# AC33GA256 register map
Vendor: ABOV Semiconductor Co., Ltd.; File version: 0.1
CPU: CM3 r1p0, little endian, no MPU, no FPU, 3 interrupt priority bits
Registers are 32-bit, read-write, reset 0x0 unless marked. A register's access mark holds for its fields unless they carry their own. Offsets are from the block's base; [hi:lo] are bit positions; {n}, {i} and the like mark numbered series.

## PMU — POWER MANAGEMENT UNIT
Base 0x40000000
0x00 IDR ro reset 0xCEDA0000 — Chip ID Register
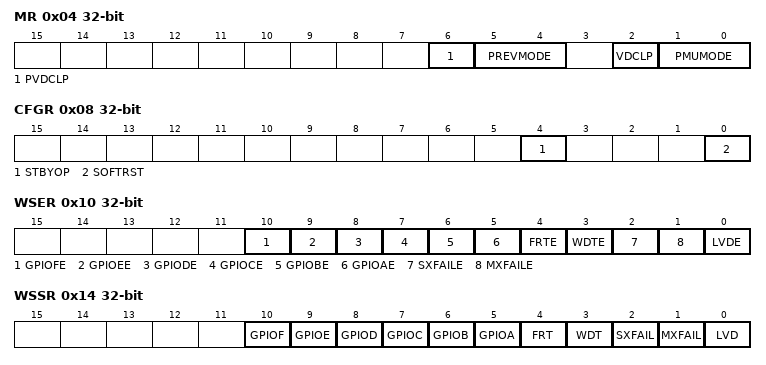
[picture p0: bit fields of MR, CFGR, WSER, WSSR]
0x04 MR — PMU Mode Register
  [6] PVDCLP, [5:4] PREVMODE, [2] VDCLP, [1:0] PMUMODE
0x08 CFGR — PMU CONFIGURATION REGISTER
  [4] STBYOP — Output polarity of STBY pin
  [0] SOFTRST — Setting for internal soft-reset
0x10 WSER — PMU Wake-up Source Enable Register
  [10] GPIOFE — Setting of the wake-up by GPIOF (PD SLEEP)
  [9] GPIOEE — Setting of the wake-up by GPIOE (PD SLEEP)
  [8] GPIODE — Setting of the wake-up by GPIOD (PD SLEEP)
  [7] GPIOCE — Setting of the wake-up by GPIOC (PD SLEEP)
  [6] GPIOBE — Setting of the wake-up by GPIOB (PD SLEEP)
  [5] GPIOAE — Setting of the wake-up by GPIO (PD SLEEP)
  [4] FRTE — Setting of the wake-up by FRT (PD SLEEP)
  [3] WDTE — Setting of the wake-up by WDT (PD SLEEP)
  [2] SXFAILE — Setting of the wake-up by the Sub OSC Fail Event(SLEEP)Setting value of the wake-up by LVD (SLEEP)
  [1] MXFAILE — Setting of the wake-up by Main OSC-fail event(SLEEP)Setting value of the wake-up by Sub OSC Fail Event (SLEEP)
  [0] LVDE — Setting of the wake-up by LVD (SLEEP)Setting value of the wake-up by Main OSC Fail Event (SLEEP)
0x14 WSSR — PMU Wak-up Source Status Register
  [10] GPIOF, [9] GPIOE, [8] GPIOD, [7] GPIOC, [6] GPIOB, [5] GPIOA, [4] FRT, [3] WDT, [2] SXFAIL, [1] MXFAIL, [0] LVD
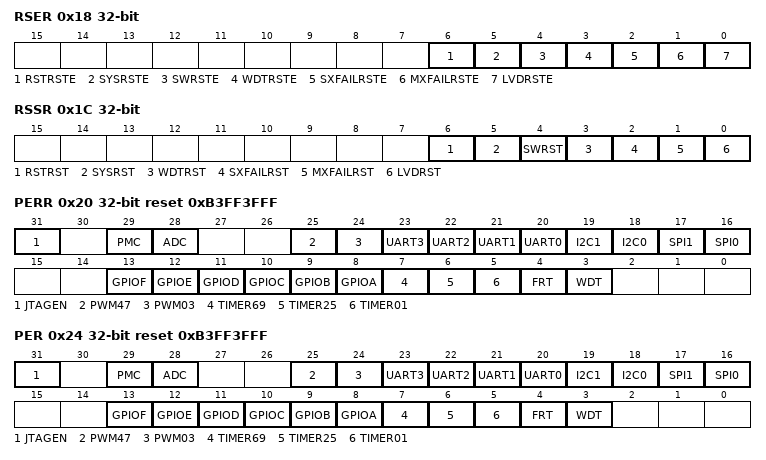
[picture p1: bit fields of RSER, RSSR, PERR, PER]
0x18 RSER — Reset Source Enable Register
  [6] RSTRSTE — Enable/Disable external nRESET pin reset
  [5] SYSRSTE — Enable/Disable SystemReset from the core
  [4] SWRSTE — Enable/Disable Software Reset in PMUCFGR
  [3] WDTRSTE — Enable/Disable WDT reset
  [2] SXFAILRSTE — Enable/Disable auxiliary oscillator failure reset
  [1] MXFAILRSTE — Enable/Disable auxiliary oscillator failure reset
  [0] LVDRSTE — Enable/Disable LVD reset
0x1C RSSR — Reset Source Status Register
  [6] RSTRST — Occurrence of external nRESET pin reset
  [5] SYSRST — Occurrence of SystemReset from the core
  [4] SWRST — Occurrence of Software Reset in PMUCFGR
  [3] WDTRST — Occurrence of WDT reset
  [2] SXFAILRST — Occurrence of auxiliary oscillator failure reset
  [1] MXFAILRST — Occurrence of auxiliary oscillator failure reset
  [0] LVDRST — Occurrence of LVD reset
0x20 PERR reset 0xB3FF3FFF — PMU Peripheral Event Reset Register
  [31] JTAGEN — Enable JTAG reset
  [29] PMC — Enable PMC (Port Map Controller) reset
  [28] ADC — Enable ADC reset
  [25] PWM47 — Enable PWM4, 5,6,7 reset
  [24] PWM03 — Enable PWM0, 1,2,3 reset
  [n+20] UART{n} (n=0..3) — Enable UART{n} reset
  [19] I2C1 — Enable I2C1 reset
  [18] I2C0 — Enable I2C0 reset
  [17] SPI1 — Enable SPI1 reset
  [16] SPI0 — Enable SPI0 reset
  [13] GPIOF — Enable GPIOF reset
  [12] GPIOE — Enable GPIOE reset
  [11] GPIOD — Enable GPIOD reset
  [10] GPIOC — Enable GPIOC reset
  [9] GPIOB — Enable GPIOB reset
  [8] GPIOA — Enable GPIOA reset
  [7] TIMER69 — Enable TIMER6, 7,8,9 reset
  [6] TIMER25 — Enable TIMER2, 3,4,5 reset
  [5] TIMER01 — Enable TIMER0, 1 reset
  [4] FRT — Enble Free-run Timer reset
  [3] WDT — Enabled Watchdog Timer reset
0x24 PER reset 0xB3FF3FFF — PMU Perpheral Enable Register
  [31] JTAGEN — JTAG enable - reset
  [29] PMC — Enable-Reset PMC
  [28] ADC — Enable-Reset ADC
  [25] PWM47 — Enable-Reset PWM4, 5,6,7
  [24] PWM03 — Enable-Reset PWM0, 1,2,3
  [n+20] UART{n} (n=0..3) — Enable-Reset UART{n}
  [19] I2C1 — Enable-Reset I2C1
  [18] I2C0 — Enable-Reset I2C0
  [17] SPI1 — Enable-Reset SPI1
  [16] SPI0 — Enable-Reset SPI0
  [13] GPIOF — Enable-Reset GPIOF
  [12] GPIOE — Enable-Reset GPIOE
  [11] GPIOD — Enable-Reset GPIOD
  [10] GPIOC — Enable-Reset GPIOC
  [9] GPIOB — Enable-Reset GPIOB
  [8] GPIOA — Enable-Reset GPIOA
  [7] TIMER69 — Enable-Reset TIMER6, 7,8,9
  [6] TIMER25 — Enable-Reset TIMER2, 3,4,5
  [5] TIMER01 — Enable-Reset TIMER0, 1
  [4] FRT — Enable-Reset Free-run Timer
  [3] WDT — Enable-Reset Watch-dog Timer
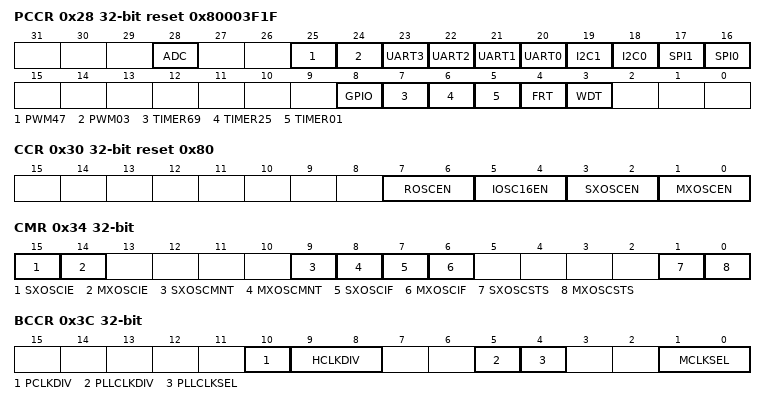
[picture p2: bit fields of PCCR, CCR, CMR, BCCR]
0x28 PCCR reset 0x80003F1F — PMU Peripheral Clock Control Register
  [28] ADC — Enable-Disable ADC clock
  [25] PWM47 — Enable-Disable PWM4, 5,6,7 clock
  [24] PWM03 — Enable-Disable PWM0, 1,2,3 clock
  [n+20] UART{n} (n=0..3) — Enable-Disable UART{n} clock
  [19] I2C1 — Enable-Disable I2C1 clock
  [18] I2C0 — Enable-Disable I2C0 clock
  [17] SPI1 — Enable-Disable SPI1 clock
  [16] SPI0 — Enable-Disable SPI0 clock
  [8] GPIO — Enable-Disable GPIO clock
  [7] TIMER69 — Enable-Disable TIMER6, 7,8,9 clock
  [6] TIMER25 — Enable-Disable TIMER2, 3,4,5 clock
  [5] TIMER01 — Enable-Disable TIMER0, 1 clock
  [4] FRT — Enable-Disable Free-run Timer clock
  [3] WDT — Enable-Disable Watch-dog Timer clock
0x30 CCR reset 0x80 — PMU Clock Control Register
  [7:6] ROSCEN — Enable internal ring oscillator
  [5:4] IOSC16EN — Enable internal 16MHz oscillator
  [3:2] SXOSCEN — Enable external sub-crystal oscillator
  [1:0] MXOSCEN — Enable external main crystal oscillator
0x34 CMR — PMU Clock Monitoring Register
  [15] SXOSCIE — Enable-Disable the interrupt event of monitoring external auxiliary crystal oscillation
  [14] MXOSCIE — Enable-Disable the interrupt event of monitoring external main crystal oscillation
  [9] SXOSCMNT — Enable-Disable the monitoring function of external auxiliary crystal oscillator
  [8] MXOSCMNT — Enable-Disable the monitoring function of external main crystal oscillator
  [7] SXOSCIF — Failure dectection flag of external auxiliary crystal oscillation (To clear this flag, write 1 to the bit)
  [6] MXOSCIF — Failure dectection flag of external main crystal oscillation (To clear this flag, write 1 to the bit)
  [1] SXOSCSTS — The oscillation status of external auxiliary crystal oscillation (To clear this flag, write 1 to the bit)
  [0] MXOSCSTS — The oscillation status of external main crystal oscillation (To clear this flag, write 1 to the bit)
0x3C BCCR — PMU BUS Clock Control Register
  [10] PCLKDIV — PCLK clock divider set
  [9:8] HCLKDIV — HCLK clock dvider set
  [5] PLLCLKDIV — PLL input clock divider
  [4] PLLCLKSEL — PLL input clock selection
  [1:0] MCLKSEL — Main clock source selection
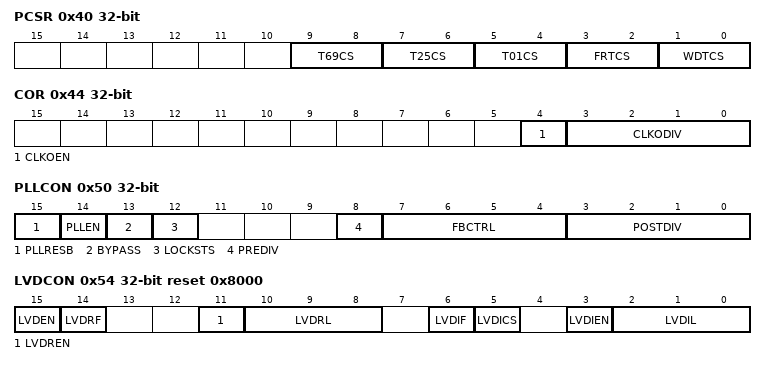
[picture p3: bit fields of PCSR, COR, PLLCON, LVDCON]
0x40 PCSR (reset mask 0x1FF) — PMU Peripheral Clock Select Register
  [9:8] T69CS — Select the timer 6,7,8,9 input clock
  [7:6] T25CS — Select timer 2,3,4,5 input clock
  [5:4] T01CS — Select timer 0,1 input clock
  [3:2] FRTCS — Select FRT input clock
  [1:0] WDTCS — Select WDT input clock
0x44 COR — PMU Clock Output Register
  [4] CLKOEN — Enable CLKO divider output
  [3:0] CLKODIV — set the value of the division of CLKO
0x50 PLLCON — PLL Control Register
  [15] PLLRESB — PLL Reset
  [14] PLLEN — PLL Enable
  [13] BYPASS — Select PLL input clock bypass
  [12] LOCKSTS ro — PLL Lock state
  [8] PREDIV — Pre-Divider division control
  [7:4] FBCTRL — Post-scaler control
  [3:0] POSTDIV — post divider
0x54 LVDCON reset 0x8000 — LVD Control Register
  [15] LVDEN — Enable LVD
  [14] LVDRF — LVD reset flag (cleared when writing 1)
  [11] LVDREN — Enable LVD Reset
  [10:8] LVDRL — Select LVD Reset voltage level
  [6] LVDIF — LVD interrupt flag (cleared when writing 1)
  [5] LVDICS ro — LVD interrupt current status
  [3] LVDIEN — Enable LVD interrupt
  [2:0] LVDIL — Select LVD Interrupt voltage level
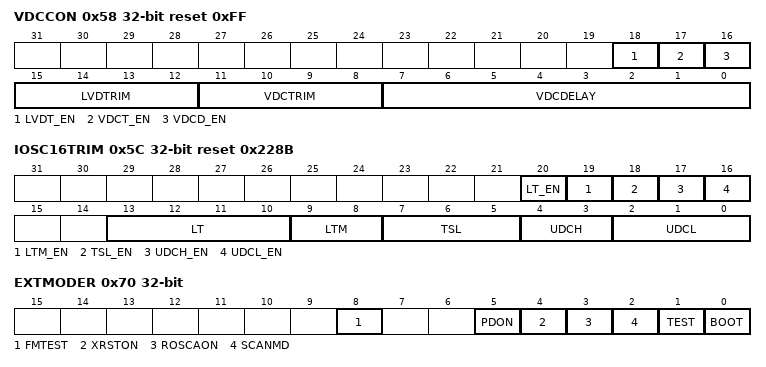
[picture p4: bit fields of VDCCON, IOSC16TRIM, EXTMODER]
0x58 VDCCON reset 0xFF — VDC/LVD Trimming Register
  [18] LVDT_EN wo — Enable writing on LVDTRIM bit field
  [17] VDCT_EN wo — Enable writing on VDCTRIM bit field
  [16] VDCD_EN wo — Enable writing on VDCDELAY bit field
  [15:12] LVDTRIM — LVD Trimming Value
  [11:8] VDCTRIM — VDC Trimming Value
  [7:0] VDCDELAY — VDC Delay Time from starting wake-up
0x5C IOSC16TRIM reset 0x228B — IOSC16 Trimming Register
  [20] LT_EN wo — Enable writing on LT bit field
  [19] LTM_EN wo — Enable writing on LTM bit field
  [18] TSL_EN wo — Enable writing on TSL bit field
  [17] UDCH_EN wo — Enable writing on UDCH bit field
  [16] UDCL_EN wo — Enable writing on UDCL bit field
  [13:10] LT
  [9:8] LTM
  [7:5] TSL
  [4:3] UDCH
  [2:0] UDCL
0x70 EXTMODER — External Mode Read Register
  [8] FMTEST wo — Set all pins to test mode
  [5] PDON ro — Read PDON pin
  [4] XRSTON ro — Read XRSTON pin
  [3] ROSCAON ro — Read ROSCAON pin
  [2] SCANMD ro — Read SCANMD pin
  [1] TEST ro — Read TEST pin
  [0] BOOT ro — Read BOOT pin
